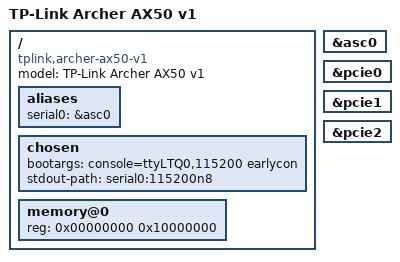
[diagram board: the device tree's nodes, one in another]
// SPDX-License-Identifier: GPL-2.0-only
/dts-v1/;

#include "grx500.dtsi"

/ {
	model = "TP-Link Archer AX50 v1";
	compatible = "tplink,archer-ax50-v1", "lantiq,grx500", "lantiq,xrx500";

	aliases {
		serial0 = &asc0;
	};

	chosen {
		bootargs = "console=ttyLTQ0,115200 earlycon";
		stdout-path = "serial0:115200n8";
	};

	memory@0 {
		device_type = "memory";
		reg = <0x00000000 0x10000000>; /* 256 MiB at physical 0x00000000 (kseg0 maps here) */
		/* NOTE: vendor Linux used mem=256M@512M (phys 0x20000000) via EVA segment remapping.
		 * Linux 6.12 without EVA segment register initialization uses standard MIPS kseg0
		 * mapping: virtual 0x80000000 → physical 0x00000000.
		 * U-Boot loads to 0x80800000 → phys 0x00800000, confirming RAM at 0x00000000. */
	};
};

&asc0 {
	status = "okay";
};

&pcie0 {
	status = "okay";
};

&pcie1 {
	status = "okay";
};

&pcie2 {
	status = "okay";
};
